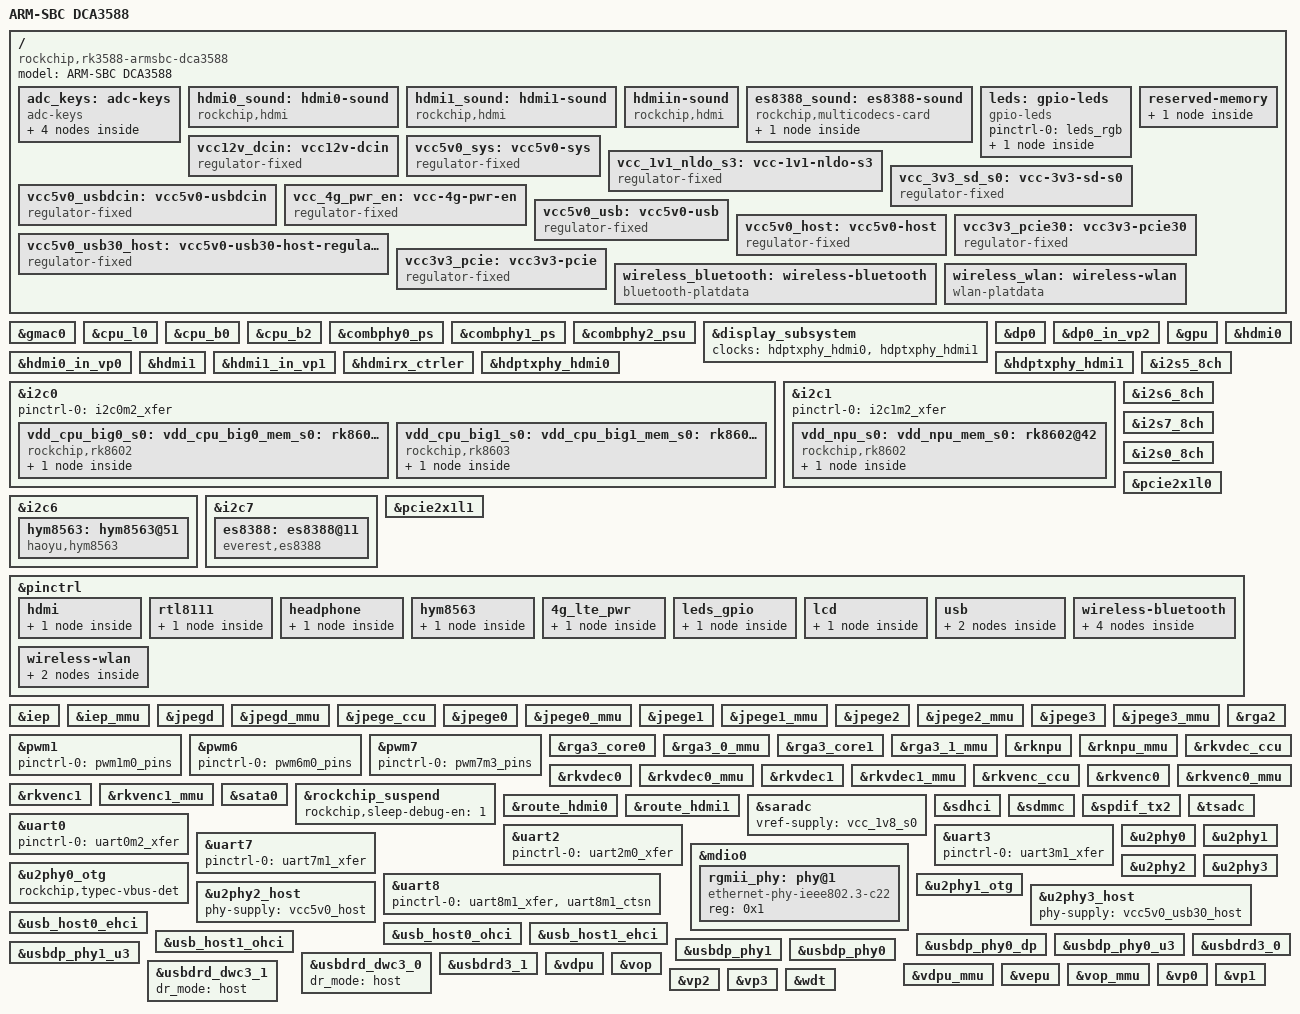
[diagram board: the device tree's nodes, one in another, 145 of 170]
// SPDX-License-Identifier: (GPL-2.0+ OR MIT)
/*
 * Copyright (c) 2021 Rockchip Electronics Co., Ltd.
 *
 */

/dts-v1/;

#include <dt-bindings/gpio/gpio.h>
#include <dt-bindings/pwm/pwm.h>
#include <dt-bindings/pinctrl/rockchip.h>
#include <dt-bindings/input/rk-input.h>
#include <dt-bindings/display/drm_mipi_dsi.h>
#include <dt-bindings/display/rockchip_vop.h>
#include <dt-bindings/sensor-dev.h> 
#include "dt-bindings/usb/pd.h"
#include "rk3588.dtsi"
#include "rk3588-rk806-single.dtsi"
#include "rk3588-linux.dtsi"

/ {
	model = "ARM-SBC DCA3588";
	compatible = "rockchip,rk3588-armsbc-dca3588", "rockchip,rk3588";
 
	/delete-node/ chosen;
 
	 adc_keys: adc-keys {
		compatible = "adc-keys";
		io-channels = <&saradc 1>;
		io-channel-names = "buttons";
		keyup-threshold-microvolt = <1800000>;
		poll-interval = <100>;
 
		vol-up-key {
			label = "volume up";
			linux,code = <KEY_VOLUMEUP>;
			press-threshold-microvolt = <17000>;
		};
 
		vol-down-key {
			label = "volume down";
			linux,code = <KEY_VOLUMEDOWN>;
			press-threshold-microvolt = <417000>;
		};
 
		menu-key {
			label = "menu";
			linux,code = <KEY_MENU>;
			press-threshold-microvolt = <890000>;
		};
 
		back-key {
			label = "back";
			linux,code = <KEY_BACK>;
			press-threshold-microvolt = <1235000>;
		};
	};
 
	hdmi0_sound: hdmi0-sound {
		status = "okay";
		compatible = "rockchip,hdmi";
		rockchip,mclk-fs = <128>;
		rockchip,card-name = "rockchip-hdmi0";
		rockchip,cpu = <&i2s5_8ch>;
		rockchip,codec = <&hdmi0>;
		rockchip,jack-det;
	};
	
	hdmi1_sound: hdmi1-sound {
		status = "okay";
		compatible = "rockchip,hdmi";
		rockchip,mclk-fs = <128>;
		rockchip,card-name = "rockchip-hdmi1";
		rockchip,cpu = <&i2s6_8ch>;
		rockchip,codec = <&hdmi1>;
		rockchip,jack-det;
	};
 
	hdmiin-sound {
		compatible = "rockchip,hdmi";
		rockchip,mclk-fs = <128>;
		rockchip,format = "i2s";
		rockchip,bitclock-master = <&hdmirx_ctrler>;
		rockchip,frame-master = <&hdmirx_ctrler>;
		rockchip,card-name = "rockchip-hdmiin";
		rockchip,cpu = <&i2s7_8ch>;
		rockchip,codec = <&hdmirx_ctrler 0>;
		rockchip,jack-det;
	};
	
	es8388_sound: es8388-sound {
		status = "okay";
		compatible = "rockchip,multicodecs-card";
		rockchip,card-name = "rockchip-es8388";
		io-channels = <&saradc 3>;
		io-channel-names = "adc-detect";
		keyup-threshold-microvolt = <1800000>;
		poll-interval = <100>;
		spk-con-gpio = <&gpio1 RK_PD3 GPIO_ACTIVE_HIGH>;
		hp-con-gpio = <&gpio1 RK_PD2 GPIO_ACTIVE_HIGH>;
		rockchip,format = "i2s";
		rockchip,mclk-fs = <256>;
		rockchip,cpu = <&i2s0_8ch>;
		rockchip,codec = <&es8388>;
		rockchip,audio-routing =
			"Headphone", "LOUT1",
			"Headphone", "ROUT1",

			"Speaker", "LOUT2",
			"Speaker", "ROUT2",
			"Headphone", "Headphone Power",
			"Headphone", "Headphone Power",
			"Speaker", "Speaker Power",
			"Speaker", "Speaker Power",
			"LINPUT1", "Main Mic",
			"LINPUT2", "Main Mic",
			"RINPUT1", "Headset Mic",
			"RINPUT2", "Headset Mic";
		pinctrl-names = "default";

		play-pause-key {
			label = "playpause";
			linux,code = <KEY_PLAYPAUSE>;
			press-threshold-microvolt = <2000>;
		};
	};
 
	leds: gpio-leds {
		compatible = "gpio-leds";
		pinctrl-names = "default";
		pinctrl-0 =<&leds_rgb>;
		status = "okay";
 
		system_led@1 {
			gpios = <&gpio4 RK_PB0 GPIO_ACTIVE_HIGH>;
			label = "system_led";
			linux,default-trigger = "heartbeat";
			linux,default-trigger-delay-ms = <0>;
		};
 
	};
 
	/* If hdmirx node is disabled, delete the reserved-memory node here. */
	reserved-memory {
		#address-cells = <2>;
		#size-cells = <2>;
		ranges;
 
		/* Reserve 256MB memory for hdmirx-controller@fdee0000 */
		cma {
			compatible = "shared-dma-pool";
			reusable;
			reg = <0x0 (256 * 0x100000) 0x0 (256 * 0x100000)>;
			linux,cma-default;
		};
	};
 
	vcc12v_dcin: vcc12v-dcin {
		compatible = "regulator-fixed";
		regulator-name = "vcc12v_dcin";
		regulator-always-on;
		regulator-boot-on;
		regulator-min-microvolt = <12000000>;
		regulator-max-microvolt = <12000000>;
	};
 
	vcc5v0_sys: vcc5v0-sys {
		compatible = "regulator-fixed";
		regulator-name = "vcc5v0_sys";
		regulator-always-on;
		regulator-boot-on;
		regulator-min-microvolt = <5000000>;
		regulator-max-microvolt = <5000000>;
		vin-supply = <&vcc12v_dcin>;
	};
 
	vcc_1v1_nldo_s3: vcc-1v1-nldo-s3 {
		compatible = "regulator-fixed";
		regulator-name = "vcc_1v1_nldo_s3";
		regulator-always-on;
		regulator-boot-on;
		regulator-min-microvolt = <1100000>;
		regulator-max-microvolt = <1100000>;
		vin-supply = <&vcc5v0_sys>;
	 };
 
	vcc_3v3_sd_s0: vcc-3v3-sd-s0 {
		compatible = "regulator-fixed";
		regulator-name = "vcc_3v3_sd_s0";
		regulator-min-microvolt = <3300000>;
		regulator-max-microvolt = <3300000>;
		pinctrl-names = "default";
		enable-active-low;
	};
 
	vcc5v0_usbdcin: vcc5v0-usbdcin {
		compatible = "regulator-fixed";
		regulator-name = "vcc5v0_usbdcin";
		regulator-always-on;
		regulator-boot-on;
		regulator-min-microvolt = <5000000>;
		regulator-max-microvolt = <5000000>;
		vin-supply = <&vcc12v_dcin>;
	};
	
	vcc_4g_pwr_en: vcc-4g-pwr-en {
		compatible = "regulator-fixed";
		regulator-name = "vcc_4g";
		gpios = <&gpio3 RK_PB4 GPIO_ACTIVE_HIGH>;
		regulator-always-on;
		regulator-boot-on;
		enable-active-high;
		regulator-min-microvolt = <5000000>;
		regulator-max-microvolt = <5000000>;
		pinctrl-0 = <&vcc4g_pwr_en>;
		vin-supply = <&vcc5v0_usbdcin>;
	};
  
	vcc5v0_usb: vcc5v0-usb {
		compatible = "regulator-fixed";
		regulator-name = "vcc5v0_usb";
		regulator-always-on;
		regulator-boot-on;
		regulator-min-microvolt = <5000000>;
		regulator-max-microvolt = <5000000>;
		vin-supply = <&vcc5v0_usbdcin>;
	};
 
	vcc5v0_host: vcc5v0-host {
		compatible = "regulator-fixed";
		regulator-name = "vcc5v0_host";
		regulator-boot-on;
		regulator-always-on;
		regulator-min-microvolt = <5000000>;
		regulator-max-microvolt = <5000000>;
		enable-active-high;
		gpio = <&gpio1 RK_PA4 GPIO_ACTIVE_HIGH>;
		vin-supply = <&vcc5v0_usb>;
		pinctrl-names = "default";
		pinctrl-0 = <&vcc5v0_host_en>;
	};
	
	vcc5v0_usb30_host: vcc5v0-usb30-host-regulator {
        	compatible = "regulator-fixed";
		regulator-name = "vcc5v0-usb30-host";
		regulator-boot-on;
        	enable-active-high;
        	regulator-always-on;
        	pinctrl-names = "default";
         	pinctrl-0= <&usb30_pwr_en_h>;
		gpio = <&gpio1 RK_PA1 GPIO_ACTIVE_HIGH>;
        	regulator-min-microvolt = <5000000>;
        	regulator-max-microvolt = <5000000>;
        	vin-supply = <&vcc5v0_sys>;
    	};
 
	vcc3v3_pcie30: vcc3v3-pcie30 {
		compatible = "regulator-fixed";
		regulator-name = "vcc3v3_pcie30";
		regulator-min-microvolt = <3300000>;
		regulator-max-microvolt = <3300000>;
		enable-active-high;
		startup-delay-us = <5000>;
		vin-supply = <&vcc5v0_sys>;
	};
	
	vcc3v3_pcie: vcc3v3-pcie {
        	compatible = "regulator-fixed";
        	regulator-name = "vcc3v3_pcie";
        	regulator-min-microvolt = <3300000>;
        	regulator-max-microvolt = <3300000>;
        	enable-active-high;
        	gpios = <&gpio2 RK_PB4 GPIO_ACTIVE_HIGH>;
        	startup-delay-us = <5000>;
        	vin-supply = <&vcc12v_dcin>;
    };

	wireless_bluetooth: wireless-bluetooth {
		compatible = "bluetooth-platdata";
		clocks = <&hym8563>;
		clock-names = "ext_clock";
		uart_rts_gpios = <&gpio3 RK_PA4 GPIO_ACTIVE_LOW>;
		pinctrl-names = "default", "rts_gpio";
		pinctrl-0 = <&uart8m1_rtsn>, <&bt_reset_gpio>, <&bt_wake_gpio>, <&bt_irq_gpio>;
		pinctrl-1 = <&uart8_gpios>;
		BT,reset_gpio    = <&gpio0 RK_PC6 GPIO_ACTIVE_HIGH>;//BT_REG_ON
		BT,wake_gpio     = <&gpio0 RK_PC5 GPIO_ACTIVE_HIGH>;//HOST_WAKE_BT
		BT,wake_host_irq = <&gpio0 RK_PA0 GPIO_ACTIVE_HIGH>;//BT_WAKE_HOST
		status = "okay";
	};
 
	wireless_wlan: wireless-wlan {
		compatible = "wlan-platdata";
		wifi_chip_type = "ap6255";
		pinctrl-names = "default";
		pinctrl-0 = <&wifi_host_wake_irq>, <&wifi_poweren_gpio>;
		WIFI,host_wake_irq = <&gpio0 RK_PB2 GPIO_ACTIVE_HIGH>;
		WIFI,poweren_gpio = <&gpio0 RK_PC4 GPIO_ACTIVE_HIGH>;
		status = "okay";
	};
 };
 	
&gmac0 {
	phy-mode = "rgmii-rxid";
	clock_in_out = "output";
	phy-supply = <&vcc_3v3_s0>;
	snps,reset-gpio = <&gpio4 RK_PB3 GPIO_ACTIVE_LOW>;
	snps,reset-active-low;
	/* Reset time is 20ms, 100ms for rtl8211f */
	snps,reset-delays-us = <0 20000 100000>;
	pinctrl-names = "default";
	pinctrl-0 = <&gmac0_miim
		     &gmac0_tx_bus2
		     &gmac0_rx_bus2
		     &gmac0_rgmii_clk
		     &eth0_pins
		     &gmac0_rgmii_bus>;
	tx_delay = <0x43>;
	rx_delay = <0x3f>; 
	phy-handle = <&rgmii_phy>;
	status = "okay";
};

&cpu_l0 {
	cpu-supply = <&vdd_cpu_lit_s0>;
	mem-supply = <&vdd_cpu_lit_mem_s0>;
};
 
&cpu_b0 {
	cpu-supply = <&vdd_cpu_big0_s0>;
	mem-supply = <&vdd_cpu_big0_mem_s0>;
};
 
&cpu_b2 {
	cpu-supply = <&vdd_cpu_big1_s0>;
	mem-supply = <&vdd_cpu_big1_mem_s0>;
};
 
&combphy0_ps {
	status = "okay";
};
 
&combphy1_ps {
	status = "okay";
};
 
&combphy2_psu {
    status = "okay";
};

&display_subsystem {
    clocks = <&hdptxphy_hdmi0>, <&hdptxphy_hdmi1>;
    clock-names = "hdmi0_phy_pll", "hdmi1_phy_pll";
};
&dp0 {
	status = "okay";
};
&dp0_in_vp2 {
	status = "okay";
};

&gpu {
    mali-supply = <&vdd_gpu_s0>;
    mem-supply = <&vdd_gpu_mem_s0>;
    status = "okay";
};

&hdmi0 {
    status = "okay";
    enable-gpios = <&gpio4 RK_PB1 GPIO_ACTIVE_HIGH>;
    cec-enable = "true";
};

&hdmi0_in_vp0 {
	status = "okay";
};

&hdmi1 {
    status = "okay";
    enable-gpios = <&gpio4 RK_PB2 GPIO_ACTIVE_HIGH>;
    cec-enable = "true";
};

&hdmi1_in_vp1 {
    status = "okay";
};

&hdmirx_ctrler {
    status = "okay";
    #sound-dai-cells = <1>;
    hpd-trigger-level = <1>;
    hdmirx-det-gpios = <&gpio2 13 GPIO_ACTIVE_LOW>;
    pinctrl-names = "default";
};

&hdptxphy_hdmi0 {
	status = "okay";
};

&hdptxphy_hdmi1 {
    status = "okay";
};

&i2c0 {
    status = "okay";
    pinctrl-names = "default";
    pinctrl-0 = <&i2c0m2_xfer>;

    vdd_cpu_big0_s0: vdd_cpu_big0_mem_s0: rk8602@42 {
        compatible = "rockchip,rk8602";
        reg = <0x42>;
        vin-supply = <&vcc5v0_sys>;
        regulator-compatible = "rk860x-reg";
        regulator-name = "vdd_cpu_big0_s0";
        regulator-min-microvolt = <550000>;
        regulator-max-microvolt = <1050000>;
        regulator-ramp-delay = <2300>;
        rockchip,suspend-voltage-selector = <1>;
        regulator-boot-on;
        regulator-always-on;
        regulator-state-mem {
            regulator-off-in-suspend;
        };
    };

    vdd_cpu_big1_s0: vdd_cpu_big1_mem_s0: rk8603@43 {
        compatible = "rockchip,rk8603";
        reg = <0x43>;
        vin-supply = <&vcc5v0_sys>;
        regulator-compatible = "rk860x-reg";
        regulator-name = "vdd_cpu_big1_s0";
        regulator-min-microvolt = <550000>;
        regulator-max-microvolt = <1050000>;
        regulator-ramp-delay = <2300>;
        rockchip,suspend-voltage-selector = <1>;
        regulator-boot-on;
        regulator-always-on;
        regulator-state-mem {
            regulator-off-in-suspend;
        };
    };
};

&i2c1 {
    status = "okay";
    pinctrl-names = "default";
    pinctrl-0 = <&i2c1m2_xfer>;

    vdd_npu_s0: vdd_npu_mem_s0: rk8602@42 {
        compatible = "rockchip,rk8602";
        reg = <0x42>;
        vin-supply = <&vcc5v0_sys>;
        regulator-compatible = "rk860x-reg";
        regulator-name = "vdd_npu_s0";
        regulator-min-microvolt = <550000>;
        regulator-max-microvolt = <950000>;
        regulator-ramp-delay = <2300>;
        rockchip,suspend-voltage-selector = <1>;
        regulator-boot-on;
        regulator-always-on;
        regulator-state-mem {
            regulator-off-in-suspend;
        };
    };
};

&i2c6 {
	status = "okay";
    	hym8563: hym8563@51 {
        	compatible = "haoyu,hym8563";
        	reg = <0x51>;
        	#clock-cells = <0>;
        	clock-frequency = <32768>;
        	clock-output-names = "hym8563";
        	pinctrl-names = "default";
        	pinctrl-0 = <&hym8563_int>;
		interrupt-parent = <&gpio0>;
		interrupts = <RK_PB0 IRQ_TYPE_LEVEL_LOW>;
        	wakeup-source;
        	status = "okay";
    };

};

&i2c7 {
    status = "okay";
    
    es8388: es8388@11 {
        status = "okay";
        #sound-dai-cells = <0>;
        compatible = "everest,es8388", "everest,es8323";
        reg = <0x11>;
        clocks = <&mclkout_i2s0>;
        clock-names = "mclk";
        assigned-clocks = <&mclkout_i2s0>;
        assigned-clock-rates = <12288000>;
        pinctrl-names = "default";
        pinctrl-0 = <&i2s0_mclk>;
    };
};

&i2s5_8ch {
	status = "okay";
};

&i2s6_8ch {
	status = "okay";
};

&i2s7_8ch {
	status = "okay";
};

&i2s0_8ch {
    status = "okay";
    pinctrl-0 = <&i2s0_lrck
             &i2s0_sclk
             &i2s0_sdi0
             &i2s0_sdo0>;
};


&pcie2x1l0 {
        reset-gpios = <&gpio1 RK_PB4 GPIO_ACTIVE_HIGH>;
        rockchip,skip-scan-in-resume;
        vpcie3v3-supply = <&vcc3v3_pcie>;
        status = "okay";
};

&pcie2x1l1 {
        reset-gpios = <&gpio4 RK_PA2 GPIO_ACTIVE_HIGH>;
        pinctrl-names = "default";
        pinctrl-0 = <&rtl8111_isolate>;
        status = "okay";
};

&pinctrl {

    	hdmi {
		hdmirx_det: hdmirx-det {
			rockchip,pins = <2 RK_PB5 RK_FUNC_GPIO &pcfg_pull_up>;
		};
	};

	rtl8111 {
                rtl8111_isolate: rtl8111-isolate {
                        rockchip,pins = <4 RK_PB6 RK_FUNC_GPIO &pcfg_pull_up>;
                };
        };
                
    	headphone {
        	hp_det: hp-det {
            	rockchip,pins = <1 RK_PD5 RK_FUNC_GPIO &pcfg_pull_none>;
        	};
    	};
    	
    	hym8563 {
		hym8563_int: hym8563-int {
			rockchip,pins = <0 RK_PB0 RK_FUNC_GPIO &pcfg_pull_up>;
		};
	};
	
	4g_lte_pwr {
	
		vcc4g_pwr_en: vcc4g-pwr-en {
			rockchip,pins = <3 RK_PB4 RK_FUNC_GPIO &pcfg_pull_up>;
		};
	};

    	leds_gpio {
        	leds_rgb: leds-rgb {
                	rockchip,pins = <4 RK_PB0 RK_FUNC_GPIO &pcfg_pull_up>;
        	};
    	};

	lcd {
		lcd_rst_gpio: lcd-rst-gpio {
			rockchip,pins = <0 RK_PD3 RK_FUNC_GPIO &pcfg_pull_none>;
		};
	};

	usb {
		vcc5v0_host_en: vcc5v0-host-en {
			rockchip,pins = <1 RK_PA4 RK_FUNC_GPIO &pcfg_pull_none>;
		};
		
		usb30_pwr_en_h: usb30-pwr-en-h {
			rockchip,pins = <1 RK_PA1 RK_FUNC_GPIO &pcfg_pull_up>;
		};
		
	};

    	wireless-bluetooth {
		uart8_gpios: uart8-gpios {
			rockchip,pins = <3 RK_PA4 RK_FUNC_GPIO &pcfg_pull_none>;
		};

		bt_reset_gpio: bt-reset-gpio {
			rockchip,pins = <0 RK_PC6 RK_FUNC_GPIO &pcfg_pull_none>;
		};

		bt_wake_gpio: bt-wake-gpio {
			rockchip,pins = <0 RK_PC5 RK_FUNC_GPIO &pcfg_pull_none>;
		};

		bt_irq_gpio: bt-irq-gpio {
			rockchip,pins = <0 RK_PA0 RK_FUNC_GPIO &pcfg_pull_none>;
		};
     	};

     	wireless-wlan {
		
		wifi_host_wake_irq: wifi-host-wake-irq {
			rockchip,pins = <0 RK_PB2 RK_FUNC_GPIO &pcfg_pull_down>;
			};
		wifi_poweren_gpio: wifi-poweren-gpio {
			rockchip,pins = <0 RK_PC4 RK_FUNC_GPIO &pcfg_pull_up>;
		};
	};

};

&iep {
	status = "okay";
};

&iep_mmu {
	status = "okay";
};

&jpegd {
	status = "okay";
};

&jpegd_mmu {
	status = "okay";
};

&jpege_ccu {
	status = "okay";
};

&jpege0 {
	status = "okay";
};

&jpege0_mmu {
	status = "okay";
};

&jpege1 {
	status = "okay";
};

&jpege1_mmu {
	status = "okay";
};

&jpege2 {
	status = "okay";
};

&jpege2_mmu {
	status = "okay";
};

&jpege3 {
	status = "okay";
};

&jpege3_mmu {
	status = "okay";
};

&pwm1 {
	pinctrl-0 = <&pwm1m0_pins>;
	status = "okay";
};

&pwm6 {
	pinctrl-0 = <&pwm6m0_pins>;
	status = "okay";
};

&pwm7 {
	pinctrl-0 = <&pwm7m3_pins>;
	status = "okay";
};

&rga2 {
	status = "okay";
};

&rga3_core0 {
	status = "okay";
};

&rga3_0_mmu {
	status = "okay";
};

&rga3_core1 {
	status = "okay";
};

&rga3_1_mmu {
	status = "okay";
};

&rknpu {
	rknpu-supply = <&vdd_npu_s0>;
	mem-supply = <&vdd_npu_mem_s0>;
	status = "okay";
};

&rknpu_mmu {
	status = "okay";
};

&rkvdec_ccu {
	status = "okay";
};

&rkvdec0 {
	status = "okay";
};

&rkvdec0_mmu {
	status = "okay";
};

&rkvdec1 {
	status = "okay";
};

&rkvdec1_mmu {
	status = "okay";
};

&rkvenc_ccu {
	status = "okay";
};

&rkvenc0 {
	venc-supply = <&vdd_vdenc_s0>;
	mem-supply = <&vdd_vdenc_mem_s0>;
	status = "okay";
};

&rkvenc0_mmu {
	status = "okay";
};

&rkvenc1 {
	venc-supply = <&vdd_vdenc_s0>;
	mem-supply = <&vdd_vdenc_mem_s0>;
	status = "okay";
};

&rkvenc1_mmu {
	status = "okay";
};

&sata0 {
    status = "okay";
};

&rockchip_suspend {
	status = "okay";
	rockchip,sleep-debug-en = <1>;
};

&route_hdmi0 {
	status = "okay";
};

&route_hdmi1 {
	status = "okay";
}; 

&saradc {
    status = "okay";
    vref-supply = <&vcc_1v8_s0>;
};

&sdhci {
    bus-width = <8>;
    no-sdio;
    no-sd;
    non-removable;
    max-frequency = <200000000>;
    mmc-hs400-1_8v;
    mmc-hs400-enhanced-strobe;
    status = "okay";
};

&sdmmc {
    max-frequency = <150000000>;
    no-sdio;
    no-mmc;
    bus-width = <4>;
    cap-mmc-highspeed;
    cap-sd-highspeed;
    disable-wp;
    sd-uhs-sdr104;
    vmmc-supply = <&vcc_3v3_sd_s0>;
    vqmmc-supply = <&vccio_sd_s0>;
    status = "okay";
};

&spdif_tx2 {
    status = "okay";
};

&uart0 {
	status = "okay";
	pinctrl-names = "default";
	pinctrl-0 = <&uart0m2_xfer>;
};

&uart2 {
	status = "okay";
	pinctrl-names = "default";
  	pinctrl-0 = <&uart2m0_xfer>;
};

&uart3 {
        status = "okay";
        pinctrl-names = "default";
        pinctrl-0 = <&uart3m1_xfer>;
};

&uart7 {
	status = "okay";
	pinctrl-names = "default";
	pinctrl-0 = <&uart7m1_xfer>;
};

&uart8 {
        status = "okay";
        pinctrl-names = "default";
        pinctrl-0 = <&uart8m1_xfer &uart8m1_ctsn>;
};

&mdio0 {
	rgmii_phy: phy@1 {
		compatible = "ethernet-phy-ieee802.3-c22";
		reg = <0x1>;
	};
};

&spdif_tx2 {
	status = "okay";
};

&tsadc {
	status = "okay";
};

&u2phy0 {
	status = "okay";
};

&u2phy0_otg {
	rockchip,typec-vbus-det;
	status = "okay";
};

&u2phy0 {
	status = "okay";
};

&u2phy1 {
	status = "okay";
};

&u2phy2 {
	status = "okay";
};

&u2phy3 {
	status = "okay";
};

&u2phy0_otg {
	status = "okay";
};

&u2phy1_otg {
	status = "okay";
};

&u2phy2_host {
	status = "okay";
	phy-supply = <&vcc5v0_host>;
};

&u2phy3_host {
	status = "okay";
	phy-supply = <&vcc5v0_usb30_host>;
};
&usb_host0_ehci {
	status = "okay";
};

&usb_host0_ohci {
	status = "okay";
};

&usb_host1_ehci {
	status = "okay";
};

&usb_host1_ohci {
	status = "okay";
};

&usbdp_phy0_dp {
	status = "okay";
};

&usbdp_phy0_u3 {
	status = "okay";
};

&usbdp_phy1 {
	status = "okay";
};

&usbdp_phy1_u3 {
	status = "okay";
};

&usb_host1_ohci {
    status = "okay";
};

&usbdp_phy0 {
	status = "okay";
};

&usbdrd_dwc3_0 {
	status = "okay";
	dr_mode = "host";	
};

&usbdrd3_0 {
    status = "okay";
};

&usbdrd3_1 {
    status = "okay";
};

&usbdrd_dwc3_1 {
    dr_mode = "host";
    status = "okay";
};

&vdpu {
    status = "okay";
};

&vdpu_mmu {
    status = "okay";
};

&vepu {
    status = "okay";
};

&vop {
    status = "okay";
};

&vop_mmu {
    status = "okay";
};

/* vp0 & vp1 splice for 8K output */
&vp0 {
	rockchip,plane-mask = <(1 << ROCKCHIP_VOP2_CLUSTER0 | 1 << ROCKCHIP_VOP2_ESMART0)>;
	rockchip,primary-plane = <ROCKCHIP_VOP2_ESMART0>;
};

&vp1 {
	rockchip,plane-mask = <(1 << ROCKCHIP_VOP2_CLUSTER1 | 1 << ROCKCHIP_VOP2_ESMART1)>;
	rockchip,primary-plane = <ROCKCHIP_VOP2_ESMART1>;
};

&vp2 {
	rockchip,plane-mask = <(1 << ROCKCHIP_VOP2_CLUSTER2 | 1 << ROCKCHIP_VOP2_ESMART2)>;
	rockchip,primary-plane = <ROCKCHIP_VOP2_ESMART2>;
};

&vp3 {
	rockchip,plane-mask = <(1 << ROCKCHIP_VOP2_CLUSTER3 | 1 << ROCKCHIP_VOP2_ESMART3)>;
	rockchip,primary-plane = <ROCKCHIP_VOP2_ESMART3>;
};

&wdt {
    status = "okay";
};

&tsadc {
    status = "okay";
};
